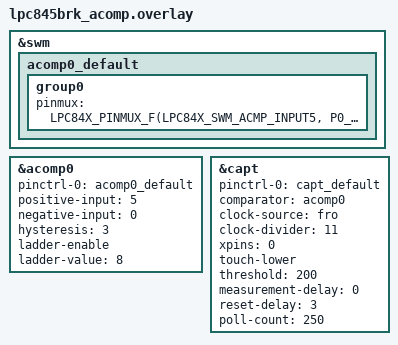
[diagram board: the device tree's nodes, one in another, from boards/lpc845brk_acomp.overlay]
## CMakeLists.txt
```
# Copyright (c) 2026 Aerlync Labs Inc
# SPDX-License-Identifier: Apache-2.0

cmake_minimum_required(VERSION 3.20.0)
find_package(Zephyr REQUIRED HINTS $ENV{ZEPHYR_BASE})

project(input_lpc8xx_capt)

FILE(GLOB app_sources src/*.c)
target_sources(app PRIVATE ${app_sources})
```

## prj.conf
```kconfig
# Copyright (c) 2026 Aerlync Labs Inc
# SPDX-License-Identifier: Apache-2.0

CONFIG_ZTEST=y
CONFIG_INPUT=y
CONFIG_INPUT_LPC845_CAP_TOUCH=y
CONFIG_INPUT_MODE_SYNCHRONOUS=y
```

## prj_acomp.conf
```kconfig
# Copyright (c) 2026 Aerlync Labs Inc
# SPDX-License-Identifier: Apache-2.0

CONFIG_INPUT_LPC845_CAP_TOUCH_ACOMP_TRIGGER=y
```

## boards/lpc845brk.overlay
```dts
/*
 * Copyright (c) 2026 Aerlync Labs Inc.
 *
 * SPDX-License-Identifier: Apache-2.0
 */

&capt {
	status = "okay";
	pinctrl-0 = <&capt_default>;
	pinctrl-names = "default";
	clock-source = "fro";
	clock-divider = <5>;
	xpins = <0>;
	touch-lower;
	threshold = <40>;
	inactive-xpins-mode = <1>;
	measurement-delay = <0>;
	reset-delay = <3>;
	poll-count = <250>;
};
```

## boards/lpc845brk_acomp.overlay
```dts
/*
 * Copyright (c) 2026 Aerlync Labs Inc.
 *
 * SPDX-License-Identifier: Apache-2.0
 */

&swm {
	acomp0_default: acomp0_default {
		group0 {
			pinmux = <LPC84X_PINMUX_F(LPC84X_SWM_ACMP_INPUT5, P0_30)>;
		};
	};
};

&acomp0 {
	status = "okay";
	pinctrl-0 = <&acomp0_default>;
	pinctrl-names = "default";
	positive-input = <5>;
	negative-input = <0>;
	hysteresis = <3>;
	ladder-enable;
	ladder-value = <8>;
};

&capt {
	status = "okay";
	pinctrl-0 = <&capt_default>;
	pinctrl-names = "default";
	comparator = <&acomp0>;
	clock-source = "fro";
	clock-divider = <11>;
	xpins = <0>;
	touch-lower;
	threshold = <200>;
	measurement-delay = <0>;
	reset-delay = <3>;
	poll-count = <250>;
};
```

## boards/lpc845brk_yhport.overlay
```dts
/*
 * Copyright (c) 2026 Aerlync Labs Inc.
 *
 * SPDX-License-Identifier: Apache-2.0
 */

&capt {
	status = "okay";
	pinctrl-0 = <&capt_default>;
	pinctrl-names = "default";
	clock-source = "fro";
	clock-divider = <5>;
	xpins = <0>;
	touch-lower;
	threshold = <47>;
	inactive-xpins-mode = <1>;
	measurement-delay = <0>;
	reset-delay = <3>;
	poll-count = <250>;
};
```

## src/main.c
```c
/*
 * Copyright (c) 2026 Aerlync Labs Inc.
 *
 * SPDX-License-Identifier: Apache-2.0
 */

#include <zephyr/kernel.h>
#include <zephyr/device.h>
#include <zephyr/ztest.h>
#include <zephyr/input/input.h>
#include <zephyr/logging/log.h>

LOG_MODULE_REGISTER(capt_test, LOG_LEVEL_DBG);

#define CAPTOUCH_NODE DT_NODELABEL(capt)

#if !DT_NODE_EXISTS(CAPTOUCH_NODE)
#error "Data tree node 'capt' is not defined!"
#endif

static void capt_event_cb(struct input_event *evt, void *user_data)
{
	ARG_UNUSED(user_data);

	if (evt->type == INPUT_EV_KEY && evt->code >= INPUT_BTN_0) {
		LOG_INF("Pin %d: %s", evt->code - INPUT_BTN_0, evt->value ? "Pressed" : "Released");
	}
}

INPUT_CALLBACK_DEFINE(DEVICE_DT_GET(CAPTOUCH_NODE), capt_event_cb, NULL);

ZTEST(capt_driver_tests, test_capt_init)
{
	const struct device *dev = DEVICE_DT_GET(CAPTOUCH_NODE);

	zassert_true(device_is_ready(dev), "CAPT device not ready!");

	k_msleep(200);
}

ZTEST_SUITE(capt_driver_tests, NULL, NULL, NULL, NULL, NULL);
```
